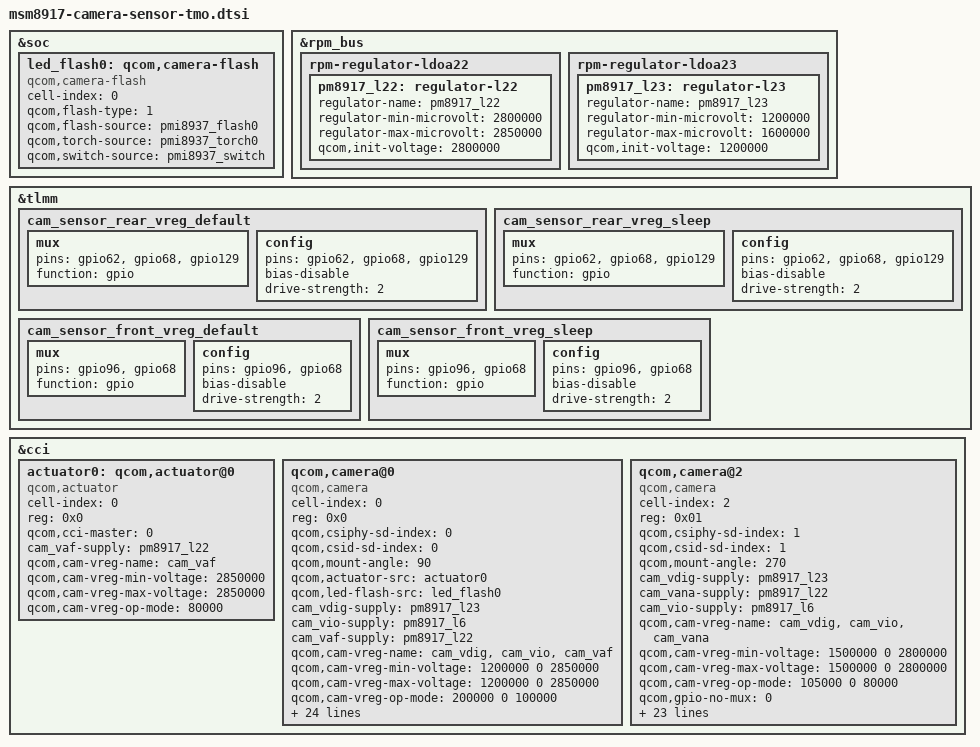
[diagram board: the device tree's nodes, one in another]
/*
 * Copyright (c) 2016, The Linux Foundation. All rights reserved.
 *
 * This program is free software; you can redistribute it and/or modify
 * it under the terms of the GNU General Public License version 2 and
 * only version 2 as published by the Free Software Foundation.
 *
 * This program is distributed in the hope that it will be useful,
 * but WITHOUT ANY WARRANTY; without even the implied warranty of
 * MERCHANTABILITY or FITNESS FOR A PARTICULAR PURPOSE.  See the
 * GNU General Public License for more details.
 */
&soc {
	led_flash0: qcom,camera-flash {
		cell-index = <0>;
		compatible = "qcom,camera-flash";
		qcom,flash-type = <1>;
		qcom,flash-source = <&pmi8937_flash0>;
		qcom,torch-source = <&pmi8937_torch0>;
		qcom,switch-source = <&pmi8937_switch>;
	};
};

&rpm_bus {
	rpm-regulator-ldoa22 {
		status = "okay";
		pm8917_l22: regulator-l22 {
			regulator-name = "pm8917_l22";
			regulator-min-microvolt = <2800000>;
			regulator-max-microvolt = <2850000>;
			qcom,init-voltage = <2800000>;
			status = "okay";
		};
	};

	rpm-regulator-ldoa23 {
		status = "okay";
		pm8917_l23: regulator-l23 {
			regulator-name = "pm8917_l23";
			regulator-min-microvolt = <1200000>;
			regulator-max-microvolt = <1600000>;
			qcom,init-voltage = <1200000>;
			status = "okay";
		};
	};
};

&tlmm{
	cam_sensor_rear_vreg_default: cam_sensor_rear_vreg_default {
		/* VDIG */
		mux {
			pins = "gpio62","gpio68","gpio129";
			function = "gpio";
		};

		config {
			pins = "gpio62","gpio68","gpio129";
			bias-disable; /* No PULL */
			drive-strength = <2>; /* 2 MA */
		};
	};

	cam_sensor_rear_vreg_sleep: cam_sensor_rear_vreg_sleep {
		/* VDIG */
		mux {
			pins = "gpio62","gpio68","gpio129";
			function = "gpio";
		};

		config {
			pins = "gpio62","gpio68","gpio129";
			bias-disable; /* No PULL */
			drive-strength = <2>; /* 2 MA */
		};
	};

	cam_sensor_front_vreg_default: cam_sensor_front_vreg_default {
		/* VDIG */
		mux {
			pins = "gpio96","gpio68";
			function = "gpio";
		};

		config {
			pins = "gpio96","gpio68";
			bias-disable; /* No PULL */
			drive-strength = <2>; /* 2 MA */
		};
	};

	cam_sensor_front_vreg_sleep: cam_sensor_front_vreg_sleep {
		/* VDIG */
		mux {
			pins = "gpio96","gpio68";
			function = "gpio";
		};

		config {
			pins = "gpio96","gpio68";
			bias-disable; /* No PULL */
			drive-strength = <2>; /* 2 MA */
		};
	};
};

&cci {
	actuator0: qcom,actuator@0 {
		cell-index = <0>;
		reg = <0x0>;
		compatible = "qcom,actuator";
		qcom,cci-master = <0>;
		cam_vaf-supply = <&pm8917_l22>;
		qcom,cam-vreg-name = "cam_vaf";
		qcom,cam-vreg-min-voltage = <2850000>;
		qcom,cam-vreg-max-voltage = <2850000>;
		qcom,cam-vreg-op-mode = <80000>;
	};

	qcom,camera@0 {
		cell-index = <0>;
		compatible = "qcom,camera";
		reg = <0x0>;
		qcom,csiphy-sd-index = <0>;
		qcom,csid-sd-index = <0>;
		qcom,mount-angle = <90>;
		qcom,actuator-src = <&actuator0>;
		qcom,led-flash-src = <&led_flash0>;
		cam_vdig-supply = <&pm8917_l23>;
		cam_vio-supply = <&pm8917_l6>;
		cam_vaf-supply = <&pm8917_l22>;
		qcom,cam-vreg-name = "cam_vdig", "cam_vio", "cam_vaf";
		qcom,cam-vreg-min-voltage = <1200000 0 2850000>;
		qcom,cam-vreg-max-voltage = <1200000 0 2850000>;
		qcom,cam-vreg-op-mode = <200000 0 100000>;
		pinctrl-names = "cam_default", "cam_suspend";
		pinctrl-0 = <&cam_sensor_mclk0_default
				&cam_sensor_rear_default
				&cam_sensor_rear_vreg_default>;
		pinctrl-1 = <&cam_sensor_mclk0_sleep
				&cam_sensor_rear_sleep
				&cam_sensor_rear_vreg_sleep>;
		gpios = <&tlmm 26 0>,
			<&tlmm 36 0>,
			<&tlmm 35 0>,
			<&tlmm 68 0>,
			<&tlmm 62 0>,
			<&tlmm 129 0>;
		qcom,gpio-reset = <1>;
		qcom,gpio-standby = <2>;
		qcom,gpio-vio = <3>;
		qcom,gpio-vdig = <4>;
		qcom,gpio-vana = <5>;
		qcom,gpio-req-tbl-num = <0 1 2 3 4 5>;
		qcom,gpio-req-tbl-flags = <1 0 0 0 0 0>;
		qcom,gpio-req-tbl-label = "CAMIF_MCLK0",
			"CAM_RESET0",
			"CAM_STANDBY0",
			"CAM_GPIO_VIO",
			"CAM_GPIO_VDIG",
			"CAM_GPIO_VANA";
		qcom,sensor-position = <0>;
		qcom,sensor-mode = <0>;
		qcom,cci-master = <0>;
		clocks = <&clock_gcc clk_mclk0_clk_src>,
			<&clock_gcc clk_gcc_camss_mclk0_clk>;
		clock-names = "cam_src_clk", "cam_clk";
		qcom,clock-rates = <24000000 0>;
	};

	qcom,camera@2 {
		cell-index = <2>;
		compatible = "qcom,camera";
		reg = <0x01>;
		qcom,csiphy-sd-index = <1>;
		qcom,csid-sd-index = <1>;
		qcom,mount-angle = <270>;
		cam_vdig-supply = <&pm8917_l23>;
		cam_vana-supply = <&pm8917_l22>;
		cam_vio-supply = <&pm8917_l6>;
		qcom,cam-vreg-name = "cam_vdig", "cam_vio", "cam_vana";
		qcom,cam-vreg-min-voltage = <1500000 0 2800000>;
		qcom,cam-vreg-max-voltage = <1500000 0 2800000>;
		qcom,cam-vreg-op-mode = <105000 0 80000>;
		qcom,gpio-no-mux = <0>;
		pinctrl-names = "cam_default", "cam_suspend";
		pinctrl-0 = <&cam_sensor_mclk2_default
				&cam_sensor_front1_default
				&cam_sensor_front_vreg_default>;
		pinctrl-1 = <&cam_sensor_mclk2_sleep
				&cam_sensor_front1_sleep
				&cam_sensor_front_vreg_sleep>;
		gpios = <&tlmm 28 0>,
			<&tlmm 40 0>,
			<&tlmm 39 0>,
			<&tlmm 68 0>,
			<&tlmm 96 0>;
		qcom,gpio-reset = <1>;
		qcom,gpio-standby = <2>;
		qcom,gpio-vio = <3>;
		qcom,gpio-vana = <4>;
		qcom,gpio-req-tbl-num = <0 1 2 3 4>;
		qcom,gpio-req-tbl-flags = <1 0 0 0 0>;
		qcom,gpio-req-tbl-label = "CAMIF_MCLK2",
					  "CAM_RESET2",
					  "CAM_STANDBY2",
					  "CAM_GPIO_VIO",
					  "CAM_GPIO_VANA";
		qcom,sensor-position = <1>;
		qcom,sensor-mode = <0>;
		qcom,cci-master = <0>;
		clocks = <&clock_gcc clk_mclk2_clk_src>,
			<&clock_gcc clk_gcc_camss_mclk2_clk>;
		clock-names = "cam_src_clk", "cam_clk";
		qcom,clock-rates = <24000000 0>;
	};
};
